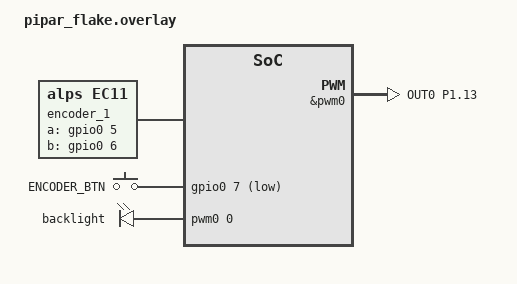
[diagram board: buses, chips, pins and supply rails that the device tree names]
/*
 * Cấu hình phần cứng cho Pipar Flake
 * Encoder + OLED + GPIO
 */

/ {
    /* 1. Cấu hình encoder */
    encoder_1: encoder_1 {
        compatible = "alps,ec11";
        a-gpios = <&gpio0 5 (GPIO_ACTIVE_HIGH | GPIO_PULL_UP)>; // P0.05
        b-gpios = <&gpio0 6 (GPIO_ACTIVE_HIGH | GPIO_PULL_UP)>; // P0.06
        steps = <24>;
    };

    /* 2. Nút nhấn encoder (nếu có) */
    buttons {
        compatible = "gpio-keys";
        encoder_btn: encoder_btn {
            gpios = <&gpio0 7 (GPIO_ACTIVE_LOW | GPIO_PULL_UP)>; // P0.07
            label = "ENCODER_BTN";
        };
    };

    /* 3. Cấu hình I2C cho màn hình OLED */
    &i2c0 {
        compatible = "nordic,nrf-twi";
        sda-pin = <20>; // P0.20
        scl-pin = <17>; // P0.17
        status = "okay";

        oled: ssd1306@3c {
            compatible = "solomon,ssd1306fb";
            reg = <0x3c>;
            width = <128>;
            height = <32>;
        };
    };

    /* 4. PWM cho backlight (nếu dùng) */
    &pwm0 {
        status = "okay";
        pinctrl-0 = <&pwm0_default>;
        pinctrl-names = "default";
    };

    &pinctrl {
        pwm0_default: pwm0_default {
            group1 {
                psels = <NRF_PSEL(PWM_OUT0, 1, 13)>; // P1.13
            };
        };
    };

    pwmleds {
        compatible = "pwm-leds";
        backlight: backlight {
            pwms = <&pwm0 0 PWM_MSEC(20) PWM_POLARITY_NORMAL>;
        };
    };
};
